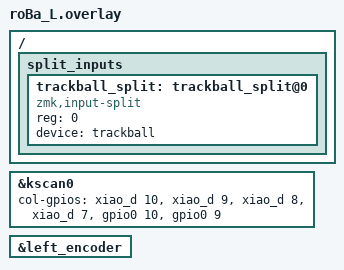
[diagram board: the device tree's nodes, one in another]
#include "roBa.dtsi"

&kscan0 {
        col-gpios
            = <&xiao_d 10 GPIO_ACTIVE_HIGH>
            , <&xiao_d 9 GPIO_ACTIVE_HIGH> 
            , <&xiao_d 8 GPIO_ACTIVE_HIGH> 
            , <&xiao_d 7 GPIO_ACTIVE_HIGH> 
            , <&gpio0 10 GPIO_ACTIVE_HIGH>
            , <&gpio0 9 GPIO_ACTIVE_HIGH>
            ;
};

/ {
    // EXACT working split inputs configuration from split-wball-44 left side
    split_inputs {
        #address-cells = <1>;
        #size-cells = <0>;

        trackball_split: trackball_split@0 {
            compatible = "zmk,input-split";
            reg = <0>;
            device = <&trackball>;
        };
    };
};

&left_encoder {
    status = "okay";
};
